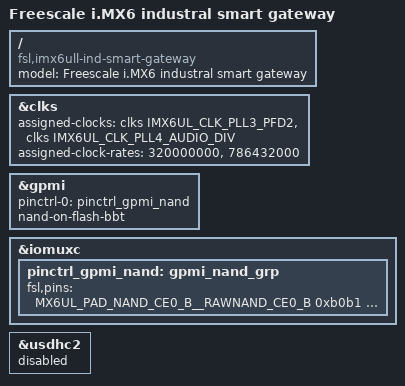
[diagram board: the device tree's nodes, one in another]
// SPDX-License-Identifier: (GPL-2.0 OR MIT)
//
// Copyright (C) 2016 Freescale Semiconductor, Inc.

/dts-v1/;

#include "imx6ull.dtsi"
#include "imx6ul-ind-smart-gateway.dtsi"

/ {
	model = "Freescale i.MX6 industral smart gateway";
	compatible = "fsl,imx6ull-ind-smart-gateway", "fsl,imx6ull";
};

&clks {
	assigned-clocks = <&clks IMX6UL_CLK_PLL3_PFD2>,
			  <&clks IMX6UL_CLK_PLL4_AUDIO_DIV>;
	assigned-clock-rates = <320000000>, <786432000>;
};

&gpmi {
	pinctrl-names = "default";
	pinctrl-0 = <&pinctrl_gpmi_nand>;
	nand-on-flash-bbt;
	status = "okay";
};

&iomuxc {
	pinctrl_gpmi_nand: gpmi_nand_grp {
		fsl,pins = <
			MX6UL_PAD_NAND_CE0_B__RAWNAND_CE0_B     0xb0b1
			MX6UL_PAD_NAND_ALE__RAWNAND_ALE         0xb0b1
			MX6UL_PAD_NAND_CLE__RAWNAND_CLE         0xb0b1
			MX6UL_PAD_NAND_RE_B__RAWNAND_RE_B       0xb0b1
			MX6UL_PAD_NAND_WE_B__RAWNAND_WE_B       0xb0b1
			MX6UL_PAD_NAND_WP_B__RAWNAND_WP_B       0xb0b1
			MX6UL_PAD_NAND_READY_B__RAWNAND_READY_B 0xb000
			MX6UL_PAD_NAND_DATA00__RAWNAND_DATA00   0xb0b1
			MX6UL_PAD_NAND_DATA01__RAWNAND_DATA01   0xb0b1
			MX6UL_PAD_NAND_DATA02__RAWNAND_DATA02   0xb0b1
			MX6UL_PAD_NAND_DATA03__RAWNAND_DATA03   0xb0b1
			MX6UL_PAD_NAND_DATA04__RAWNAND_DATA04   0xb0b1
			MX6UL_PAD_NAND_DATA05__RAWNAND_DATA05   0xb0b1
			MX6UL_PAD_NAND_DATA06__RAWNAND_DATA06   0xb0b1
			MX6UL_PAD_NAND_DATA07__RAWNAND_DATA07   0xb0b1
		>;
	};
};

&usdhc2 {
	status = "disabled";
};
